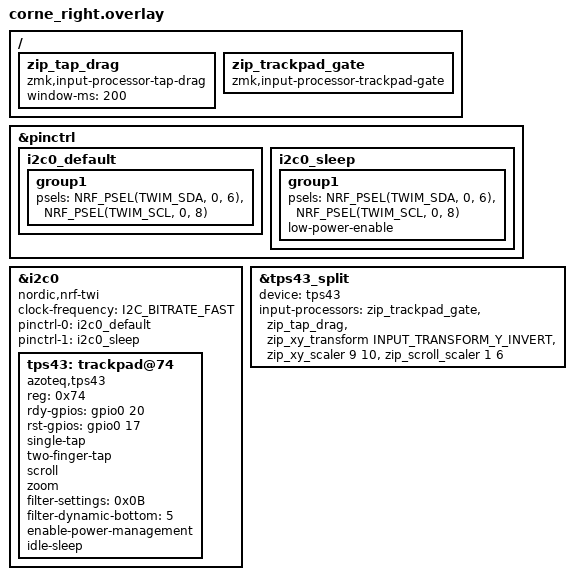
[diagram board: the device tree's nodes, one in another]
#include "corne.dtsi"
#include <dt-bindings/zmk/input_transform.h>
#include <input/processors.dtsi>
#include <zephyr/dt-bindings/i2c/i2c.h>

/ {
    // Laptop-style tap / tap-and-drag / double tap (modules/tap_drag). Also eats
    // the driver's INPUT_BTN_TOUCH, which ZMK would treat as a held left click.
    zip_tap_drag: zip_tap_drag {
        compatible = "zmk,input-processor-tap-drag";
        #input-processor-cells = <0>;
        window-ms = <200>;
    };

    // Drops trackpad input while &tp_toggle has it off (modules/trackpad_toggle).
    zip_trackpad_gate: zip_trackpad_gate {
        compatible = "zmk,input-processor-trackpad-gate";
        #input-processor-cells = <0>;
    };
};

&pinctrl {
    i2c0_default: i2c0_default {
        group1 {
            psels = <NRF_PSEL(TWIM_SDA, 0, 6)>,
                    <NRF_PSEL(TWIM_SCL, 0, 8)>;
        };
    };
    i2c0_sleep: i2c0_sleep {
        group1 {
            psels = <NRF_PSEL(TWIM_SDA, 0, 6)>,
                    <NRF_PSEL(TWIM_SCL, 0, 8)>;
            low-power-enable;
        };
    };
};

&i2c0 {
    status = "okay";
    compatible = "nordic,nrf-twi";
    clock-frequency = <I2C_BITRATE_FAST>;
    pinctrl-0 = <&i2c0_default>;
    pinctrl-1 = <&i2c0_sleep>;
    pinctrl-names = "default", "sleep";

    tps43: trackpad@74 {
        status = "okay";
        compatible = "azoteq,tps43";
        reg = <0x74>;

        rdy-gpios = <&gpio0 20 GPIO_ACTIVE_HIGH>;
        // This driver drives RST "active" to release the chip from reset, so the
        // flag must be ACTIVE_HIGH even though the IQS5xx NRST pin is active-low.
        rst-gpios = <&gpio0 17 GPIO_ACTIVE_HIGH>;

        single-tap;
        two-finger-tap;
        scroll;
        zoom;

        // 0x0B = IIR + MAV + ALP filters with the dynamic (speed-based) IIR.
        // The driver default 0x0F selects the static IIR, which ignores the
        // dynamic settings below. Bottom beta 5 matches the old AYM1607 setup.
        filter-settings = <0x0B>;
        filter-dynamic-bottom = <5>;

        enable-power-management;
        idle-sleep;
    };
};

&tps43_split {
    device = <&tps43>;
    input-processors = <&zip_trackpad_gate>,
                       <&zip_tap_drag>,
                       <&zip_xy_transform INPUT_TRANSFORM_Y_INVERT>,
                       <&zip_xy_scaler 9 10>,
                       // Scroll at 1/6. Done here rather than with the driver's
                       // scroll-sensitivity, which drops the remainder and loses slow scrolls.
                       <&zip_scroll_scaler 1 6>;
};
